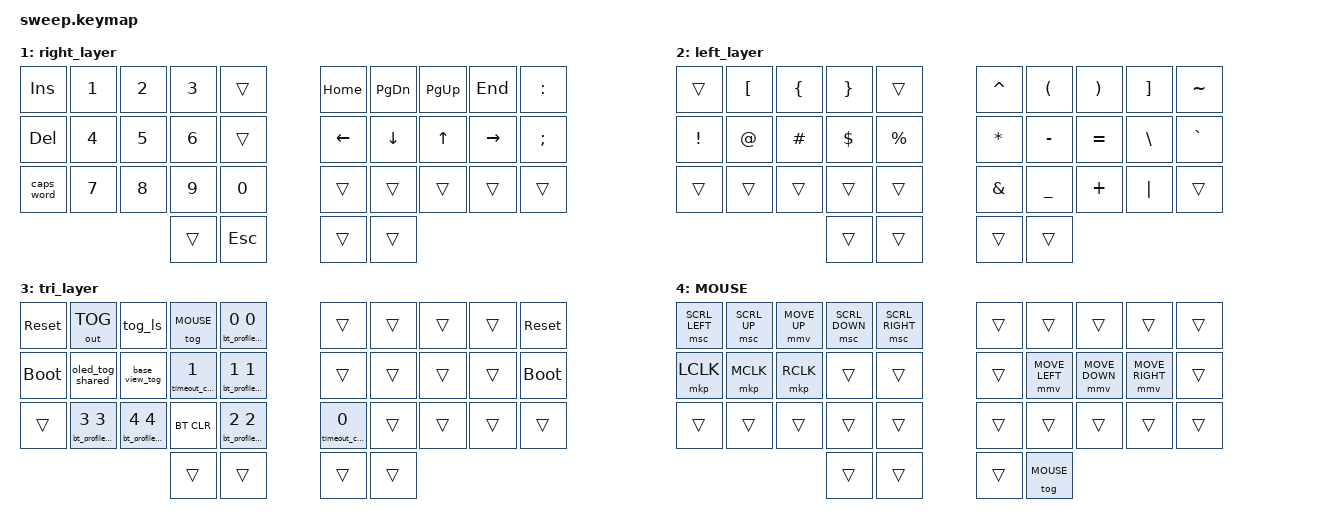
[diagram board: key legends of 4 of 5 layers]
// Copyright (c) 2022 The ZMK Contributors
// SPDX-License-Identifier: MIT

#include <behaviors.dtsi>
#include <dt-bindings/zmk/keys.h>
#include <dt-bindings/zmk/bt.h>
#include <dt-bindings/zmk/outputs.h>
#include <dt-bindings/zmk/pointing.h>
#include "../common/studio_features.dtsi"
#include "../common/studio_runtime_layers.dtsi"

#define MOUSE 4

// Give the standard pointer behaviors readable names in ZMK Studio.
// The upstream behavior bindings accept display-name, but do not define
// runtime-editable or runtime-default-active.
&mmv {
    display-name = "Mouse Move";
};

&msc {
    display-name = "Mouse Scroll";
};

&mkp {
    display-name = "Mouse Click";
};


// Keep Sweep's existing home-row mod timing and tap-preferred feel.
&mt {
    flavor = "tap-preferred";
    tapping-term-ms = <220>;
    quick-tap-ms = <150>;
    require-prior-idle-ms = <100>;
};

// Sweep's direct-scan GPIO order is defined in sweep_matrix.dtsi.


// Home row mods macro
#define HRML(k1,k2,k3,k4) &mt LSHFT k1  &mt LALT k2  &mt LCTRL k3  &mt LGUI k4
#define HRMR(k1,k2,k3,k4) &mt RGUI k1  &mt RCTRL k2  &mt RALT k3  &mt RSHFT k4

/ {
    conditional_layers {
        compatible = "zmk,conditional-layers";
        tri_layer {
            if-layers = <1 2>;
            then-layer = <3>;
        };
    };

    combos {
        compatible = "zmk,combos";
        studio_unlock_combo {
            key-positions = <0 1>;
            layers = <0>;
            timeout-ms = <50>;
            require-prior-idle-ms = <500>;
            bindings = <&studio_unlock>;
        };
    };

    behaviors {
        base_view_tog: base_view_toggle {
            compatible = "zmk,behavior-base-view-toggle";
            #binding-cells = <0>;
            display-name = "BASE View Cycle";
        };
    };

    keymap {
        compatible = "zmk,keymap";
        default_layer {
            bindings = <
        //╭──────────┬──────────┬──────────┬──────────┬──────────╮   ╭──────────┬──────────┬──────────┬──────────┬──────────╮
        //│  Q       │  W       │  E       │  R       │  T       │   │  Y       │  U       │  I       │  O       │  P       │
            &kp Q      &kp W      &kp E      &kp R      &kp T          &kp Y      &kp U      &kp I      &kp O      &kp P
        //├──────────┼──────────┼──────────┼──────────┼──────────┤   ├──────────┼──────────┼──────────┼──────────┼──────────┤
        //│  A       │  S       │  D       │  F       │  G       │   │  H       │  J       │  K       │  L       │ ' "      │
            HRML(A,        S,         D,         F)     &kp G          &kp H      HRMR(J,        K,         L,        SQT)
        //├──────────┼──────────┼──────────┼──────────┼──────────┤   ├──────────┼──────────┼──────────┼──────────┼──────────┤
        //│  Z       │  X       │  C       │  V       │  B       │   │  N       │  M       │ , <      │ . >      │ / ?      │
            &kp Z      &kp X      &kp C      &kp V      &kp B          &kp N      &kp M      &kp COMMA  &kp DOT    &kp FSLH
        //╰──────────┴──────────┴──────────┼──────────┼──────────┤   ├──────────┼──────────┼──────────┴──────────┴──────────╯
                                            &lt 2 TAB   &kp ENTER     &kp SPACE  &lt 1 BSPC
        //                                 ╰──────────┴──────────╯   ╰──────────┴──────────╯
            >;
        };

        right_layer {
            bindings = <
        //╭──────────┬──────────┬──────────┬──────────┬──────────╮   ╭──────────┬──────────┬──────────┬──────────┬──────────╮
        //│ INSERT   │  1       │  2       │  3       │          │   │ HOME     │ PAGE DN  │ PAGE UP  │ END      │  :       │
            &kp INS    &kp N1     &kp N2     &kp N3     &trans         &kp HOME   &kp PG_DN  &kp PG_UP  &kp END    &kp COLON
        //├──────────┼──────────┼──────────┼──────────┼──────────┤   ├──────────┼──────────┼──────────┼──────────┼──────────┤
        //│ DELETE   │  4       │  5       │  6       │          │   │ LEFT     │ DOWN     │ UP       │ RIGHT    │  ;       │
            &kp DEL    &kp N4     &kp N5     &kp N6     &trans         &kp LEFT   &kp DOWN   &kp UP   &kp RIGHT   &kp SEMI
        //├──────────┼──────────┼──────────┼──────────┼──────────┤   ├──────────┼──────────┼──────────┼──────────┼──────────┤
        //│ CAPS     │  7       │  8       │  9       │  0       │   │          │          │          │          │          │
           &caps_word  &kp N7     &kp N8     &kp N9     &kp N0         &trans     &trans     &trans     &trans     &trans
        //╰──────────┴──────────┴──────────┼──────────┼──────────┤   ├──────────┼──────────┼──────────┴──────────┴──────────╯
                                             &trans     &kp ESC        &trans     &trans
        //                                 ╰──────────┴──────────╯   ╰──────────┴──────────╯
            >;
        };

        left_layer {
            bindings = <
        //╭──────────┬──────────┬──────────┬──────────┬──────────╮   ╭──────────┬──────────┬──────────┬──────────┬──────────╮
        //│          │  [       │  {       │  }       │          │   │  ^       │  (       │  )       │  ]       │  ~       │
            &trans     &kp LBKT   &kp LBRC   &kp RBRC   &trans         &kp CARET  &kp LPAR   &kp RPAR   &kp RBKT   &kp TILDE
        //├──────────┼──────────┼──────────┼──────────┼──────────┤   ├──────────┼──────────┼──────────┼──────────┼──────────┤
        //│  !       │  @       │  #       │  $       │  %       │   │  *       │  -       │  =       │  \       │  `       │
            &kp EXCL   &kp AT     &kp HASH   &kp DLLR   &kp PRCNT      &kp ASTRK  &kp MINUS  &kp EQUAL  &kp BSLH   &kp GRAVE
        //├──────────┼──────────┼──────────┼──────────┼──────────┤   ├──────────┼──────────┼──────────┼──────────┼──────────┤
        //│          │          │          │          │          │   │  &       │  _       │  +       │  │       │          │
            &trans     &trans     &trans     &trans     &trans         &kp AMPS   &kp UNDER  &kp PLUS   &kp PIPE   &trans
        //╰──────────┴──────────┴──────────┼──────────┼──────────┤   ├──────────┼──────────┼──────────┴──────────┴──────────╯
                                             &trans     &trans         &trans     &trans
        //                                 ╰──────────┴──────────╯   ╰──────────┴──────────╯
            >;
        };

        tri_layer {
            bindings = <
        //╭──────────┬──────────┬──────────┬──────────┬──────────╮   ╭──────────┬──────────┬──────────┬──────────┬──────────╮
        //│ RESET    │          │          │          │PROFILE 0 │   │          │          │          │          │  RESET   │
           &sys_reset  &out OUT_TOG &tog_ls    &tog MOUSE &bt_profile_shared 0 0    &trans     &trans     &trans     &trans    &sys_reset
        //├──────────┼──────────┼──────────┼──────────┼──────────┤   ├──────────┼──────────┼──────────┼──────────┼──────────┤
        //│BOOTLOADER│          │          │          │PROFILE 1 │   │          │          │          │          │BOOTLOADER│
          &bootloader  &oled_tog_shared &base_view_tog &timeout_cycle_shared 1 &bt_profile_shared 1 1    &trans     &trans     &trans     &trans    &bootloader
        //├──────────┼──────────┼──────────┼──────────┼──────────┤   ├──────────┼──────────┼──────────┼──────────┼──────────┤
        //│          │          │          │ CLEAR BT │PROFILE 2 │   │          │          │          │          │          │
            &trans     &bt_profile_shared 3 3 &bt_profile_shared 4 4 &bt BT_CLR &bt_profile_shared 2 2    &timeout_cycle_shared 0 &trans     &trans     &trans     &trans
        //╰──────────┴──────────┴──────────┼──────────┼──────────┤   ├──────────┼──────────┼──────────┴──────────┴──────────╯
                                             &trans     &trans         &trans     &trans
        //                                 ╰──────────┴──────────╯   ╰──────────┴──────────╯
            >;
        };

        mouse_layer {
            display-name = "MOUSE";
            bindings = <
                &msc SCRL_LEFT &msc SCRL_UP &mmv MOVE_UP &msc SCRL_DOWN &msc SCRL_RIGHT &trans &trans &trans &trans &trans
                &mkp LCLK &mkp MCLK &mkp RCLK &trans &trans &trans &mmv MOVE_LEFT &mmv MOVE_DOWN &mmv MOVE_RIGHT &trans
                &trans &trans &trans &trans &trans &trans &trans &trans &trans &trans
                &trans &trans &trans &tog MOUSE
            >;
        };

        ZMK_STUDIO_RUNTIME_LAYER_SLOTS_4
    };
};
